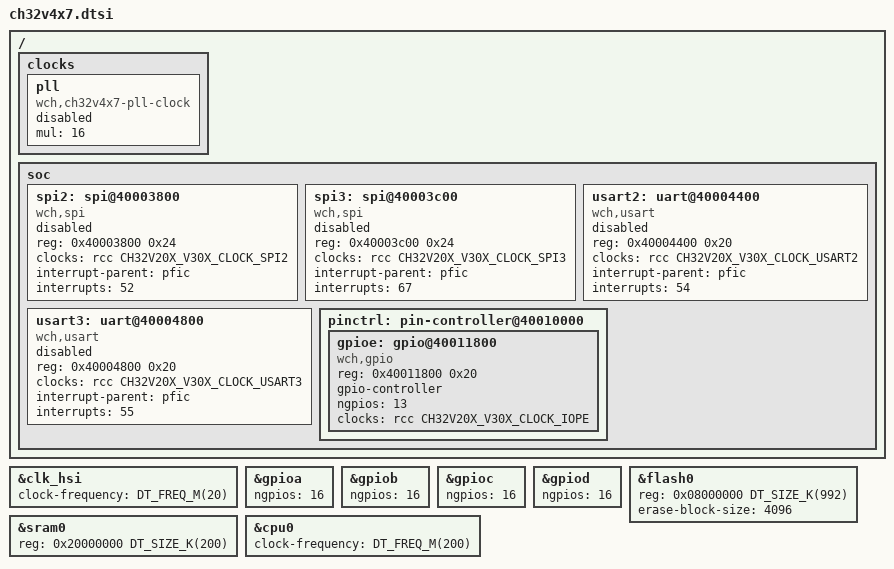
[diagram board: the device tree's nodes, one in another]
/*
 * Copyright (c) 2026 Adafruit Industries
 *
 * SPDX-License-Identifier: Apache-2.0
 */

/*
 * CH32V407 / CH32V467. The peripheral map and interrupt numbers follow the
 * CH32V30x for the blocks described here (CH32V407 RM figure 1-2 and the
 * vector table in WCH's startup_ch32v4x7.S). I2C2 is replaced by I3C.
 */

#include <wch/qingke-v3v.dtsi>
#include <wch/common/ch32v20x_30x_common.dtsi>

/delete-node/ &pll;

/ {
	clocks {
		pll: pll {
			compatible = "wch,ch32v4x7-pll-clock";
			#clock-cells = <0>;
			mul = <16>;
			status = "disabled";
		};
	};

	soc {
		spi2: spi@40003800 {
			compatible = "wch,spi";
			reg = <0x40003800 0x24>;
			clocks = <&rcc CH32V20X_V30X_CLOCK_SPI2>;
			interrupt-parent = <&pfic>;
			interrupts = <52>;
			#address-cells = <1>;
			#size-cells = <0>;
			status = "disabled";
		};

		spi3: spi@40003c00 {
			compatible = "wch,spi";
			reg = <0x40003c00 0x24>;
			clocks = <&rcc CH32V20X_V30X_CLOCK_SPI3>;
			interrupt-parent = <&pfic>;
			interrupts = <67>;
			#address-cells = <1>;
			#size-cells = <0>;
			status = "disabled";
		};

		usart2: uart@40004400 {
			compatible = "wch,usart";
			reg = <0x40004400 0x20>;
			clocks = <&rcc CH32V20X_V30X_CLOCK_USART2>;
			interrupt-parent = <&pfic>;
			interrupts = <54>;
			status = "disabled";
		};

		usart3: uart@40004800 {
			compatible = "wch,usart";
			reg = <0x40004800 0x20>;
			clocks = <&rcc CH32V20X_V30X_CLOCK_USART3>;
			interrupt-parent = <&pfic>;
			interrupts = <55>;
			status = "disabled";
		};

		pinctrl: pin-controller@40010000 {
			gpioe: gpio@40011800 {
				compatible = "wch,gpio";
				reg = <0x40011800 0x20>;
				gpio-controller;
				#gpio-cells = <2>;
				ngpios = <13>;
				clocks = <&rcc CH32V20X_V30X_CLOCK_IOPE>;
			};
		};
	};
};

&clk_hsi {
	clock-frequency = <DT_FREQ_M(20)>;
};

&gpioa {
	ngpios = <16>;
};

&gpiob {
	ngpios = <16>;
};

&gpioc {
	ngpios = <16>;
};

&gpiod {
	ngpios = <16>;
};

/* 992 KiB of code flash. The first 512 KiB run with zero wait states (RM 1.2.1). */
&flash0 {
	reg = <0x08000000 DT_SIZE_K(992)>;
	ranges = <0x0 0x08000000 DT_SIZE_K(992)>;
	erase-block-size = <4096>;
};

&sram0 {
	reg = <0x20000000 DT_SIZE_K(200)>;
};

&cpu0 {
	clock-frequency = <DT_FREQ_M(200)>;
};
